# ESP32-C3 register map
Vendor: ESPRESSIF SYSTEMS (SHANGHAI) CO., LTD.; Series: ESP32-C3; File version: 10
CPU: RV32IMC r0p0, little endian, no MPU, no FPU, 4 interrupt priority bits
Address unit: 32 bits
Registers are 32-bit, read-write, reset 0x0 unless marked. A register's access mark holds for its fields unless they carry their own. Offsets are from the block's base; [hi:lo] are bit positions; {n}, {i} and the like mark numbered series.

## LEDC — LED Control PWM (Pulse Width Modulation)
Base 0x60019000
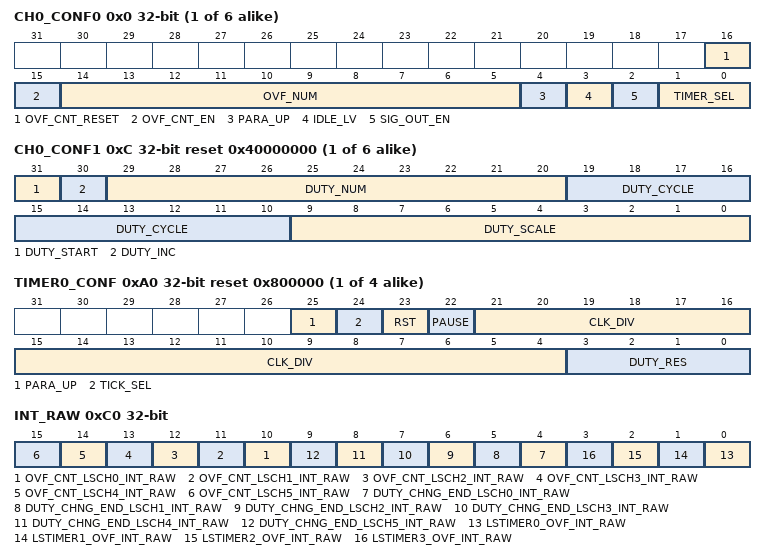
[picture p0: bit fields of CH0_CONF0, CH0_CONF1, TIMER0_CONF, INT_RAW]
{0x0+0x14*i} CH{i}_CONF0 (i=0..5) access per field — LEDC_LSCH{i}_CONF{i}.
  [16] OVF_CNT_RESET wo — reg_ovf_cnt_reset_lsch0.
  [15] OVF_CNT_EN rw — reg_ovf_cnt_en_lsch0.
  [14:5] OVF_NUM rw — reg_ovf_num_lsch0.
  [4] PARA_UP wo — reg_para_up_lsch0.
  [3] IDLE_LV rw — reg_idle_lv_lsch0.
  [2] SIG_OUT_EN rw — reg_sig_out_en_lsch0.
  [1:0] TIMER_SEL rw — reg_timer_sel_lsch0.
{0x4+0x14*i} CH{i}_HPOINT (i=0..5) — LEDC_LSCH{i}_HPOINT.
  [13:0] HPOINT — reg_hpoint_lsch0.
{0x8+0x14*i} CH{i}_DUTY (i=0..5) — LEDC_LSCH{i}_DUTY.
  [18:0] DUTY — reg_duty_lsch0.
{0xC+0x14*i} CH{i}_CONF1 (i=0..5) reset 0x40000000 — LEDC_LSCH{i}_CONF1.
  [31] DUTY_START — reg_duty_start_lsch0.
  [30] DUTY_INC — reg_duty_inc_lsch0.
  [29:20] DUTY_NUM — reg_duty_num_lsch0.
  [19:10] DUTY_CYCLE — reg_duty_cycle_lsch0.
  [9:0] DUTY_SCALE — reg_duty_scale_lsch0.
{0x10+0x14*i} CH{i}_DUTY_R (i=0..5) ro — LEDC_LSCH{i}_DUTY_R.
  [18:0] DUTY_R — reg_duty_lsch0_r.
{0xA0+8i} TIMER{i}_CONF (i=0..3) access per field reset 0x800000 — LEDC_LSTIMER{i}_CONF.
  [25] PARA_UP wo — reg_lstimer0_para_up.
  [24] TICK_SEL rw — reg_tick_sel_lstimer0.
  [23] RST rw — reg_lstimer0_rst.
  [22] PAUSE rw — reg_lstimer0_pause.
  [21:4] CLK_DIV rw — reg_clk_div_lstimer0.
  [3:0] DUTY_RES rw — reg_lstimer0_duty_res.
{0xA4+8i} TIMER{i}_VALUE (i=0..3) ro — LEDC_LSTIMER{i}_VALUE.
  [13:0] CNT — reg_lstimer0_cnt.
0xC0 INT_RAW ro — LEDC_INT_RAW.
  [n+10] OVF_CNT_LSCH{n}_INT_RAW (n=0..5) — reg_ovf_cnt_lsch{n}_int_raw.
  [n+4] DUTY_CHNG_END_LSCH{n}_INT_RAW (n=0..5) — reg_duty_chng_end_lsch{n}_int_raw.
  [n] LSTIMER{n}_OVF_INT_RAW (n=0..3) — reg_lstimer{n}_ovf_int_raw.
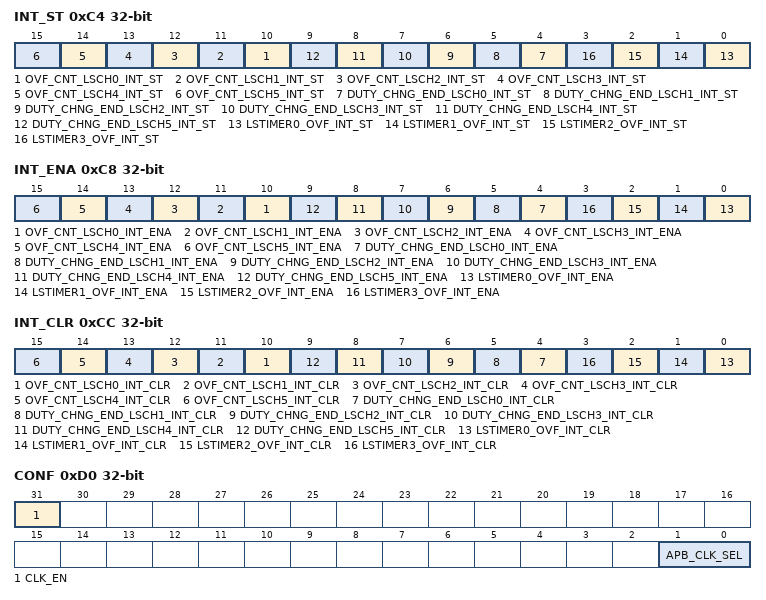
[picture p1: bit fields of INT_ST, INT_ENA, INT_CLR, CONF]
0xC4 INT_ST ro — LEDC_INT_ST.
  [n+10] OVF_CNT_LSCH{n}_INT_ST (n=0..5) — reg_ovf_cnt_lsch{n}_int_st.
  [n+4] DUTY_CHNG_END_LSCH{n}_INT_ST (n=0..5) — reg_duty_chng_end_lsch{n}_int_st.
  [n] LSTIMER{n}_OVF_INT_ST (n=0..3) — reg_lstimer{n}_ovf_int_st.
0xC8 INT_ENA — LEDC_INT_ENA.
  [n+10] OVF_CNT_LSCH{n}_INT_ENA (n=0..5) — reg_ovf_cnt_lsch{n}_int_ena.
  [n+4] DUTY_CHNG_END_LSCH{n}_INT_ENA (n=0..5) — reg_duty_chng_end_lsch{n}_int_ena.
  [n] LSTIMER{n}_OVF_INT_ENA (n=0..3) — reg_lstimer{n}_ovf_int_ena.
0xCC INT_CLR wo — LEDC_INT_CLR.
  [n+10] OVF_CNT_LSCH{n}_INT_CLR (n=0..5) — reg_ovf_cnt_lsch{n}_int_clr.
  [n+4] DUTY_CHNG_END_LSCH{n}_INT_CLR (n=0..5) — reg_duty_chng_end_lsch{n}_int_clr.
  [n] LSTIMER{n}_OVF_INT_CLR (n=0..3) — reg_lstimer{n}_ovf_int_clr.
0xD0 CONF — LEDC_CONF.
  [31] CLK_EN — reg_clk_en.
  [1:0] APB_CLK_SEL — reg_apb_clk_sel.
0xFC DATE reset 0x19061700 — LEDC_DATE.
  [31:0] LEDC_DATE — reg_ledc_date.

## RNG — Hardware random number generator
Base 0x60026000
0xB0 DATA access not given — Random number data

## RSA — RSA (Rivest Shamir Adleman) Accelerator
Base 0x6003C000
{0x0+i} M_MEM[{i}] (i=0..15) 8-bit access not given — The memory that stores M
{0x200+i} Z_MEM[{i}] (i=0..15) 8-bit access not given — The memory that stores Z
{0x400+i} Y_MEM[{i}] (i=0..15) 8-bit access not given — The memory that stores Y
{0x600+i} X_MEM[{i}] (i=0..15) 8-bit access not given — The memory that stores X
0x800 M_PRIME — RSA M_prime register
  [31:0] M_PRIME — Those bits stores m'
0x804 MODE — RSA mode register
  [6:0] MODE — rsa mode (rsa length).
0x808 QUERY_CLEAN ro — RSA query clean register
  [0] QUERY_CLEAN
0x80C SET_START_MODEXP wo — RSA modular exponentiation trigger register.
  [0] SET_START_MODEXP — start modular exponentiation
0x810 SET_START_MODMULT wo — RSA modular multiplication trigger register.
  [0] SET_START_MODMULT — start modular multiplication
0x814 SET_START_MULT wo — RSA normal multiplication trigger register.
  [0] SET_START_MULT — start multiplicaiton
0x818 QUERY_IDLE ro — RSA query idle register
  [0] QUERY_IDLE — query rsa idle. 1'b0: busy, 1'b1: idle
0x81C INT_CLR wo — RSA interrupt clear register
  [0] CLEAR_INTERRUPT — set this bit to clear RSA interrupt.
0x820 CONSTANT_TIME reset 0x1 — RSA constant time option register
  [0] CONSTANT_TIME — Configure this bit to 0 for acceleration. 0: with acceleration, 1: without acceleration(defalut).
0x824 SEARCH_ENABLE — RSA search option
  [0] SEARCH_ENABLE — Configure this bit to 1 for acceleration. 1: with acceleration, 0: without acceleration(default). This option should be used together with RSA_SEARCH_POS.
0x828 SEARCH_POS — RSA search position configure register
  [11:0] SEARCH_POS — Configure this field to set search position. This field should be used together with RSA_SEARCH_ENABLE. The field is only meaningful when RSA_SEARCH_ENABLE is high.
0x82C INT_ENA — RSA interrupt enable register
  [0] INT_ENA — Set this bit to enable interrupt that occurs when rsa calculation is done. 1'b0: disable, 1'b1: enable(default).
0x830 DATE reset 0x20200618 — RSA version control register
  [29:0] DATE — rsa version information
